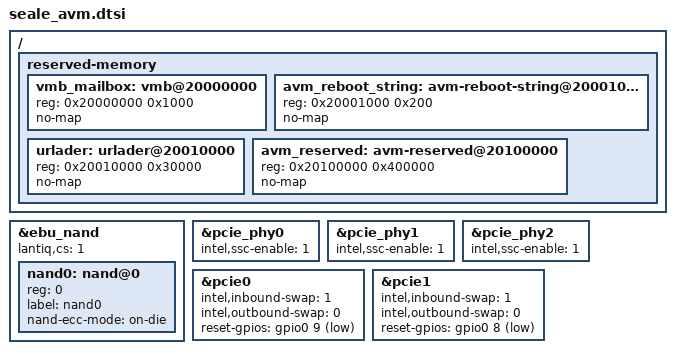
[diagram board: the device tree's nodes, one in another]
// SPDX-License-Identifier: GPL-2.0-only
// Copyright (C) 2026 Grische <github@grische.xyz>
/*
 * AVM FRITZ!Box boards on the Lantiq/Intel xRX500 (Seale) SoC family.
 * Board-family layer: everything common to every FRITZ!Box on this SoC, but
 * nothing that is on the die. SoC-level description is in xrx500.dtsi;
 * per-board data is in the board .dts.
 */

#include <dt-bindings/gpio/gpio.h>

#include "xrx500.dtsi"

/*
 * Every FRITZ!Box on this SoC wires its flash to EBU chip-select 1, with the
 * chip data window decoded at 0x17c00000. Both facts are in the vendor device
 * tree (lantiq,cs = <1>, and the localbus ranges that place the window).
 */
&ebu_nand {
	status = "okay";

	lantiq,cs = <1>;

	nand0: nand@0 {
		reg = <0>;
		label = "nand0";

		/*
		 * On-die ECC, selected through the legacy "nand-ecc-mode"
		 * property on purpose: the modern "nand-ecc-engine" spelling is
		 * a phandle, and a string there fails phandle resolution
		 * silently, leaving the engine type at INVALID with no
		 * diagnostic.
		 */
		nand-ecc-mode = "on-die";
	};
};

/ {
	reserved-memory {
		#address-cells = <1>;
		#size-cells = <1>;
		ranges;

		/*
		 * The bottom of RAM belongs to the resident boot loader, not
		 * to Linux. MIPS runs memblock bottom-up and
		 * early_init_fdt_scan_reserved_mem() runs before
		 * bootmem_init(), so without these no-map reservations the
		 * first early allocations land on the firmware mailbox and on
		 * the loader's own image.
		 */
		vmb_mailbox: vmb@20000000 {
			reg = <0x20000000 0x1000>;
			no-map;
		};

		avm_reboot_string: avm-reboot-string@20001000 {
			reg = <0x20001000 0x200>;
			no-map;
		};

		urlader: urlader@20010000 {
			reg = <0x20010000 0x30000>;
			no-map;
		};

		/*
		 * Four megabytes immediately below the kernel load address;
		 * the vendor reserves the same range for its own crash log. A
		 * board that places ramoops inside this range must narrow
		 * this node to match.
		 */
		avm_reserved: avm-reserved@20100000 {
			reg = <0x20100000 0x400000>;
			no-map;
		};
	};
};

/*
 * All three serdes PHYs and the two root complexes that carry radios. PERST#
 * is active low on every port, spread-spectrum clocking is on, and inbound
 * byte swapping is on because the SoC is big-endian and the DesignWare core
 * is not.
 */
&pcie_phy0 {
	status = "okay";
	intel,ssc-enable = <1>;
};

&pcie_phy1 {
	status = "okay";
	intel,ssc-enable = <1>;
};

&pcie_phy2 {
	status = "okay";
	intel,ssc-enable = <1>;
};

&pcie0 {
	status = "okay";
	intel,inbound-swap = <1>;
	intel,outbound-swap = <0>;
	reset-gpios = <&gpio0 9 GPIO_ACTIVE_LOW>;
};

&pcie1 {
	status = "okay";
	intel,inbound-swap = <1>;
	intel,outbound-swap = <0>;
	reset-gpios = <&gpio0 8 GPIO_ACTIVE_LOW>;
};
